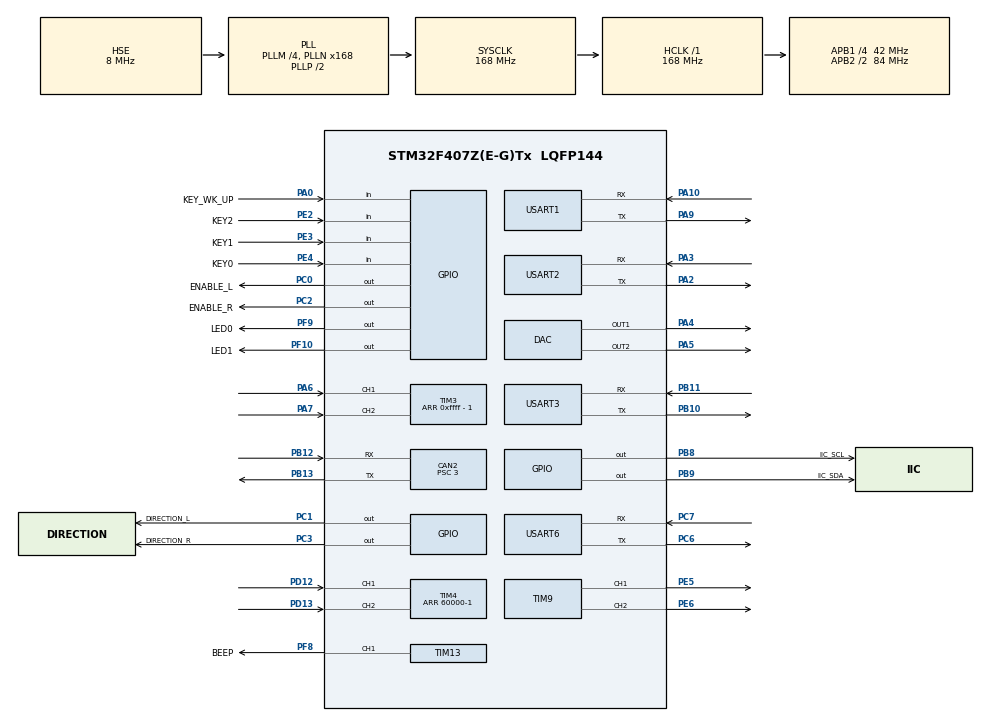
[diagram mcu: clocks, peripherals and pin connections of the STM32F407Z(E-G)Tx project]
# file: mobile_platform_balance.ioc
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CAN2.BS1=CAN_BS1_9TQ
CAN2.BS2=CAN_BS2_4TQ
CAN2.CalculateTimeQuantum=71.42857142857143
CAN2.Prescaler=3
CAN2.TXFP=ENABLE
Dma.Request0=USART2_RX
Dma.Request1=USART2_TX
Dma.Request2=USART6_RX
Dma.Request3=USART6_TX
Dma.Request4=USART1_RX
Dma.Request5=USART1_TX
Dma.Request6=USART3_RX
Dma.Request7=USART3_TX
Dma.USART1_RX.4.Direction=DMA_PERIPH_TO_MEMORY
Dma.USART1_RX.4.FIFOMode=DMA_FIFOMODE_DISABLE
Dma.USART1_RX.4.Instance=DMA2_Stream2
Dma.USART1_RX.4.MemDataAlignment=DMA_MDATAALIGN_BYTE
Dma.USART1_RX.4.MemInc=DMA_MINC_ENABLE
Dma.USART1_RX.4.Mode=DMA_NORMAL
Dma.USART1_RX.4.PeriphDataAlignment=DMA_PDATAALIGN_BYTE
Dma.USART1_RX.4.PeriphInc=DMA_PINC_DISABLE
Dma.USART1_RX.4.Priority=DMA_PRIORITY_LOW
Dma.USART1_TX.5.Direction=DMA_MEMORY_TO_PERIPH
Dma.USART1_TX.5.FIFOMode=DMA_FIFOMODE_DISABLE
Dma.USART1_TX.5.Instance=DMA2_Stream7
Dma.USART1_TX.5.MemDataAlignment=DMA_MDATAALIGN_BYTE
Dma.USART1_TX.5.MemInc=DMA_MINC_ENABLE
Dma.USART1_TX.5.Mode=DMA_NORMAL
Dma.USART1_TX.5.PeriphDataAlignment=DMA_PDATAALIGN_BYTE
Dma.USART1_TX.5.PeriphInc=DMA_PINC_DISABLE
Dma.USART1_TX.5.Priority=DMA_PRIORITY_LOW
Dma.USART2_RX.0.Direction=DMA_PERIPH_TO_MEMORY
Dma.USART2_RX.0.FIFOMode=DMA_FIFOMODE_DISABLE
Dma.USART2_RX.0.Instance=DMA1_Stream5
Dma.USART2_RX.0.MemDataAlignment=DMA_MDATAALIGN_BYTE
Dma.USART2_RX.0.MemInc=DMA_MINC_ENABLE
Dma.USART2_RX.0.Mode=DMA_NORMAL
Dma.USART2_RX.0.PeriphDataAlignment=DMA_PDATAALIGN_BYTE
Dma.USART2_RX.0.PeriphInc=DMA_PINC_DISABLE
Dma.USART2_RX.0.Priority=DMA_PRIORITY_LOW
Dma.USART2_TX.1.Direction=DMA_MEMORY_TO_PERIPH
Dma.USART2_TX.1.FIFOMode=DMA_FIFOMODE_DISABLE
Dma.USART2_TX.1.Instance=DMA1_Stream6
Dma.USART2_TX.1.MemDataAlignment=DMA_MDATAALIGN_BYTE
Dma.USART2_TX.1.MemInc=DMA_MINC_ENABLE
Dma.USART2_TX.1.Mode=DMA_NORMAL
Dma.USART2_TX.1.PeriphDataAlignment=DMA_PDATAALIGN_BYTE
Dma.USART2_TX.1.PeriphInc=DMA_PINC_DISABLE
Dma.USART2_TX.1.Priority=DMA_PRIORITY_LOW
Dma.USART3_RX.6.Direction=DMA_PERIPH_TO_MEMORY
Dma.USART3_RX.6.FIFOMode=DMA_FIFOMODE_DISABLE
Dma.USART3_RX.6.Instance=DMA1_Stream1
Dma.USART3_RX.6.MemDataAlignment=DMA_MDATAALIGN_BYTE
Dma.USART3_RX.6.MemInc=DMA_MINC_ENABLE
Dma.USART3_RX.6.Mode=DMA_NORMAL
Dma.USART3_RX.6.PeriphDataAlignment=DMA_PDATAALIGN_BYTE
Dma.USART3_RX.6.PeriphInc=DMA_PINC_DISABLE
Dma.USART3_RX.6.Priority=DMA_PRIORITY_LOW
Dma.USART3_TX.7.Direction=DMA_MEMORY_TO_PERIPH
Dma.USART3_TX.7.FIFOMode=DMA_FIFOMODE_DISABLE
Dma.USART3_TX.7.Instance=DMA1_Stream3
Dma.USART3_TX.7.MemDataAlignment=DMA_MDATAALIGN_BYTE
Dma.USART3_TX.7.MemInc=DMA_MINC_ENABLE
Dma.USART3_TX.7.Mode=DMA_NORMAL
Dma.USART3_TX.7.PeriphDataAlignment=DMA_PDATAALIGN_BYTE
Dma.USART3_TX.7.PeriphInc=DMA_PINC_DISABLE
Dma.USART3_TX.7.Priority=DMA_PRIORITY_LOW
Dma.USART6_RX.2.Direction=DMA_PERIPH_TO_MEMORY
Dma.USART6_RX.2.FIFOMode=DMA_FIFOMODE_DISABLE
Dma.USART6_RX.2.Instance=DMA2_Stream1
Dma.USART6_RX.2.MemDataAlignment=DMA_MDATAALIGN_BYTE
Dma.USART6_RX.2.MemInc=DMA_MINC_ENABLE
Dma.USART6_RX.2.Mode=DMA_NORMAL
Dma.USART6_RX.2.PeriphDataAlignment=DMA_PDATAALIGN_BYTE
Dma.USART6_RX.2.PeriphInc=DMA_PINC_DISABLE
Dma.USART6_RX.2.Priority=DMA_PRIORITY_LOW
Dma.USART6_TX.3.Direction=DMA_MEMORY_TO_PERIPH
Dma.USART6_TX.3.FIFOMode=DMA_FIFOMODE_DISABLE
Dma.USART6_TX.3.Instance=DMA2_Stream6
Dma.USART6_TX.3.MemDataAlignment=DMA_MDATAALIGN_BYTE
Dma.USART6_TX.3.MemInc=DMA_MINC_ENABLE
Dma.USART6_TX.3.Mode=DMA_NORMAL
Dma.USART6_TX.3.PeriphDataAlignment=DMA_PDATAALIGN_BYTE
Dma.USART6_TX.3.PeriphInc=DMA_PINC_DISABLE
Dma.USART6_TX.3.Priority=DMA_PRIORITY_LOW
FREERTOS.INCLUDE_vTaskDelayUntil=1
FREERTOS.Tasks01=defaultTask,0,128,StartDefaultTask,Default,NULL
Mcu.Family=STM32F4
Mcu.Name=STM32F407Z(E-G)Tx
Mcu.Package=LQFP144
NVIC.CAN2_RX1_IRQn=true\:5\:0\:false\:false\:true\:true\:true
NVIC.CAN2_TX_IRQn=true\:5\:0\:false\:false\:true\:true\:true
NVIC.DMA1_Stream1_IRQn=true\:5\:0\:false\:false\:true\:true\:false
NVIC.DMA1_Stream3_IRQn=true\:5\:0\:false\:false\:true\:true\:false
NVIC.DMA1_Stream5_IRQn=true\:5\:0\:false\:false\:true\:true\:false
NVIC.DMA1_Stream6_IRQn=true\:5\:0\:false\:false\:true\:true\:false
NVIC.DMA2_Stream1_IRQn=true\:5\:0\:false\:false\:true\:true\:false
NVIC.DMA2_Stream2_IRQn=true\:5\:0\:false\:false\:true\:true\:false
NVIC.DMA2_Stream6_IRQn=true\:5\:0\:false\:false\:true\:true\:false
NVIC.DMA2_Stream7_IRQn=true\:5\:0\:false\:false\:true\:true\:false
NVIC.PriorityGroup=NVIC_PRIORITYGROUP_4
NVIC.TIM1_BRK_TIM9_IRQn=true\:5\:0\:false\:false\:true\:true\:true
NVIC.TIM3_IRQn=true\:5\:0\:false\:false\:true\:true\:true
NVIC.TIM4_IRQn=true\:5\:0\:false\:false\:true\:true\:true
NVIC.USART1_IRQn=true\:5\:0\:false\:false\:true\:true\:true
NVIC.USART2_IRQn=true\:5\:0\:false\:false\:true\:true\:true
NVIC.USART3_IRQn=true\:5\:0\:false\:false\:true\:true\:true
NVIC.USART6_IRQn=true\:5\:0\:false\:false\:true\:true\:true
PA0-WKUP.GPIO_Label=KEY_WK_UP
PA0-WKUP.GPIO_PuPd=GPIO_PULLDOWN
PA0-WKUP.Signal=GPIO_Input
PA10.Mode=Asynchronous
PA10.Signal=USART1_RX
PA13.Mode=Serial_Wire
PA13.Signal=SYS_JTMS-SWDIO
PA14.Mode=Serial_Wire
PA14.Signal=SYS_JTCK-SWCLK
PA2.Mode=Asynchronous
PA2.Signal=USART2_TX
PA3.Mode=Asynchronous
PA3.Signal=USART2_RX
PA4.Signal=COMP_DAC1_group
PA5.Signal=COMP_DAC2_group
PA6.Signal=S_TIM3_CH1
PA7.Signal=S_TIM3_CH2
PA9.Mode=Asynchronous
PA9.Signal=USART1_TX
PB10.Mode=Asynchronous
PB10.Signal=USART3_TX
PB11.Mode=Asynchronous
PB11.Signal=USART3_RX
PB12.Mode=Slave
PB12.Signal=CAN2_RX
PB13.Mode=Slave
PB13.Signal=CAN2_TX
PB3.GPIO_PuPd=GPIO_PULLDOWN
PB3.Signal=S_TIM2_CH2
PB8.GPIO_Label=IIC_SCL
PB8.GPIO_PuPd=GPIO_PULLUP
PB8.Signal=GPIO_Output
PB9.GPIO_Label=IIC_SDA
PB9.GPIO_PuPd=GPIO_PULLUP
PB9.Signal=GPIO_Output
PC0.GPIO_Label=ENABLE_L
PC0.Signal=GPIO_Output
PC1.GPIO_Label=DIRECTION_L
PC1.Signal=GPIO_Output
PC2.GPIO_Label=ENABLE_R
PC2.Signal=GPIO_Output
PC3.GPIO_Label=DIRECTION_R
PC3.Signal=GPIO_Output
PC6.Mode=Asynchronous
PC6.Signal=USART6_TX
PC7.Mode=Asynchronous
PC7.Signal=USART6_RX
PD12.Signal=S_TIM4_CH1
PD13.Signal=S_TIM4_CH2
PE2.GPIO_Label=KEY2
PE2.GPIO_PuPd=GPIO_PULLUP
PE2.Signal=GPIO_Input
PE3.GPIO_Label=KEY1
PE3.GPIO_PuPd=GPIO_PULLUP
PE3.Signal=GPIO_Input
PE4.GPIO_Label=KEY0
PE4.GPIO_PuPd=GPIO_PULLUP
PE4.Signal=GPIO_Input
PE5.GPIO_PuPd=GPIO_PULLDOWN
PE5.Signal=S_TIM9_CH1
PE6.GPIO_PuPd=GPIO_PULLDOWN
PE6.Signal=S_TIM9_CH2
PF10.GPIO_Label=LED1
PF10.Signal=GPIO_Output
PF8.GPIO_Label=BEEP
PF8.Signal=S_TIM13_CH1
PF9.GPIO_Label=LED0
PF9.Signal=GPIO_Output
PH0-OSC_IN.Mode=HSE-External-Oscillator
PH0-OSC_IN.Signal=RCC_OSC_IN
PH1-OSC_OUT.Mode=HSE-External-Oscillator
PH1-OSC_OUT.Signal=RCC_OSC_OUT
ProjectManager.HeapSize=0x1000
ProjectManager.StackSize=0x2000
ProjectManager.TargetToolchain=MDK-ARM V5
RCC.48MHZClocksFreq_Value=84000000
RCC.AHBFreq_Value=168000000
RCC.APB1CLKDivider=RCC_HCLK_DIV4
RCC.APB1Freq_Value=42000000
RCC.APB1TimFreq_Value=84000000
RCC.APB2CLKDivider=RCC_HCLK_DIV2
RCC.APB2Freq_Value=84000000
RCC.APB2TimFreq_Value=168000000
RCC.CortexFreq_Value=168000000
RCC.HCLKFreq_Value=168000000
RCC.HSE_VALUE=8000000
RCC.HSI_VALUE=16000000
RCC.LSE_VALUE=32768
RCC.PLLM=4
RCC.PLLN=168
RCC.PLLSourceVirtual=RCC_PLLSOURCE_HSE
RCC.SYSCLKFreq_VALUE=168000000
RCC.SYSCLKSource=RCC_SYSCLKSOURCE_PLLCLK
RCC.VCOOutputFreq_Value=336000000
SH.COMP_DAC1_group.0=DAC_OUT1,DAC_OUT1
SH.COMP_DAC2_group.0=DAC_OUT2,DAC_OUT2
SH.S_TIM13_CH1.0=TIM13_CH1,PWM Generation1 CH1
SH.S_TIM2_CH2.0=TIM2_CH2
SH.S_TIM3_CH1.0=TIM3_CH1,Encoder_Interface
SH.S_TIM3_CH2.0=TIM3_CH2,Encoder_Interface
SH.S_TIM4_CH1.0=TIM4_CH1,Encoder_Interface
SH.S_TIM4_CH2.0=TIM4_CH2,Encoder_Interface
SH.S_TIM9_CH1.0=TIM9_CH1,PWM Generation1 CH1
SH.S_TIM9_CH2.0=TIM9_CH2,PWM Generation2 CH2
TIM13.Channel=TIM_CHANNEL_1
TIM3.EncoderMode=TIM_ENCODERMODE_TI12
TIM3.Period=0xffff - 1
TIM4.EncoderMode=TIM_ENCODERMODE_TI12
TIM4.Period=60000-1
TIM9.Channel-PWM\ Generation1\ CH1=TIM_CHANNEL_1
TIM9.Channel-PWM\ Generation2\ CH2=TIM_CHANNEL_2
USART1.VirtualMode=VM_ASYNC
USART2.VirtualMode=VM_ASYNC
USART3.VirtualMode=VM_ASYNC
USART6.VirtualMode=VM_ASYNC
VP_FREERTOS_VS_ENABLE.Mode=Enabled
VP_TIM13_VS_ClockSourceINT.Mode=Enable_Timer
board=custom

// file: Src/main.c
/**
  ******************************************************************************
  * @file           : main.c
  * @brief          : Main program body
  ******************************************************************************
  * This notice applies to any and all portions of this file
  * that are not between comment pairs USER CODE BEGIN and
  * USER CODE END. Other portions of this file, whether
  * inserted by the user or by software development tools
  * are owned by their respective copyright owners.
  *
  * Copyright (c) 2019 STMicroelectronics International N.V.
  * All rights reserved.
  *
  * Redistribution and use in source and binary forms, with or without
  * modification, are permitted, provided that the following conditions are met:
  *
  * 1. Redistribution of source code must retain the above copyright notice,
  *    this list of conditions and the following disclaimer.
  * 2. Redistributions in binary form must reproduce the above copyright notice,
  *    this list of conditions and the following disclaimer in the documentation
  *    and/or other materials provided with the distribution.
  * 3. Neither the name of STMicroelectronics nor the names of other
  *    contributors to this software may be used to endorse or promote products
  *    derived from this software without specific written permission.
  * 4. This software, including modifications and/or derivative works of this
  *    software, must execute solely and exclusively on microcontroller or
  *    microprocessor devices manufactured by or for STMicroelectronics.
  * 5. Redistribution and use of this software other than as permitted under
  *    this license is void and will automatically terminate your rights under
  *    this license.
  *
  * THIS SOFTWARE IS PROVIDED BY STMICROELECTRONICS AND CONTRIBUTORS "AS IS"
  * AND ANY EXPRESS, IMPLIED OR STATUTORY WARRANTIES, INCLUDING, BUT NOT
  * LIMITED TO, THE IMPLIED WARRANTIES OF MERCHANTABILITY, FITNESS FOR A
  * PARTICULAR PURPOSE AND NON-INFRINGEMENT OF THIRD PARTY INTELLECTUAL PROPERTY
  * RIGHTS ARE DISCLAIMED TO THE FULLEST EXTENT PERMITTED BY LAW. IN NO EVENT
  * SHALL STMICROELECTRONICS OR CONTRIBUTORS BE LIABLE FOR ANY DIRECT, INDIRECT,
  * INCIDENTAL, SPECIAL, EXEMPLARY, OR CONSEQUENTIAL DAMAGES (INCLUDING, BUT NOT
  * LIMITED TO, PROCUREMENT OF SUBSTITUTE GOODS OR SERVICES; LOSS OF USE, DATA,
  * OR PROFITS; OR BUSINESS INTERRUPTION) HOWEVER CAUSED AND ON ANY THEORY OF
  * LIABILITY, WHETHER IN CONTRACT, STRICT LIABILITY, OR TORT (INCLUDING
  * NEGLIGENCE OR OTHERWISE) ARISING IN ANY WAY OUT OF THE USE OF THIS SOFTWARE,
  * EVEN IF ADVISED OF THE POSSIBILITY OF SUCH DAMAGE.
  *
  ******************************************************************************
  */
#include "main.h"
#include "stm32f4xx_hal.h"
#include "cmsis_os.h"
#include "can.h"
#include "dac.h"
#include "dma.h"
#include "tim.h"
#include "usart.h"
#include "gpio.h"

/* USER CODE BEGIN Includes */
#include "sys_config.h"
/* USER CODE END Includes */

/* USER CODE BEGIN PV */
/* Private variables ---------------------------------------------------------*/

/* USER CODE END PV */

void SystemClock_Config(void);
void MX_FREERTOS_Init(void);

/* USER CODE BEGIN PFP */
/* Private function prototypes -----------------------------------------------*/

/* USER CODE END PFP */

int main(void)
{

  /* MCU Configuration----------------------------------------------------------*/

  /* Reset of all peripherals, Initializes the Flash interface and the Systick. */
  HAL_Init();

  /* Configure the system clock */
  SystemClock_Config();

  /* Initialize all configured peripherals */
  MX_GPIO_Init();
  MX_DMA_Init();
  MX_USART1_UART_Init();
  MX_TIM13_Init();
  MX_CAN2_Init();
  MX_USART2_UART_Init();
  MX_USART3_UART_Init();
  MX_USART6_UART_Init();
  MX_TIM3_Init();
  MX_TIM4_Init();
  MX_TIM9_Init();
  MX_DAC_Init();
  /* USER CODE BEGIN 2 */
	can_filter_init(&hcan2);
  /* USER CODE END 2 */

  /* Call init function for freertos objects (in freertos.c) */
  MX_FREERTOS_Init();

  /* Start scheduler */
  osKernelStart();

  /* We should never get here as control is now taken by the scheduler */

  /* Infinite loop */
  while (1)
  {

  }

}

void SystemClock_Config(void)
{

  RCC_OscInitTypeDef RCC_OscInitStruct;
  RCC_ClkInitTypeDef RCC_ClkInitStruct;

    /**Configure the main internal regulator output voltage
    */
  __HAL_RCC_PWR_CLK_ENABLE();

  __HAL_PWR_VOLTAGESCALING_CONFIG(PWR_REGULATOR_VOLTAGE_SCALE1);

    /**Initializes the CPU, AHB and APB busses clocks
    */
  RCC_OscInitStruct.OscillatorType = RCC_OSCILLATORTYPE_HSE;
  RCC_OscInitStruct.HSEState = RCC_HSE_ON;
  RCC_OscInitStruct.PLL.PLLState = RCC_PLL_ON;
  RCC_OscInitStruct.PLL.PLLSource = RCC_PLLSOURCE_HSE;
  RCC_OscInitStruct.PLL.PLLM = 4;
  RCC_OscInitStruct.PLL.PLLN = 168;
  RCC_OscInitStruct.PLL.PLLP = RCC_PLLP_DIV2;
  RCC_OscInitStruct.PLL.PLLQ = 4;
  if (HAL_RCC_OscConfig(&RCC_OscInitStruct) != HAL_OK)
  {
    _Error_Handler(__FILE__, __LINE__);
  }

    /**Initializes the CPU, AHB and APB busses clocks
    */
  RCC_ClkInitStruct.ClockType = RCC_CLOCKTYPE_HCLK|RCC_CLOCKTYPE_SYSCLK
                              |RCC_CLOCKTYPE_PCLK1|RCC_CLOCKTYPE_PCLK2;
  RCC_ClkInitStruct.SYSCLKSource = RCC_SYSCLKSOURCE_PLLCLK;
  RCC_ClkInitStruct.AHBCLKDivider = RCC_SYSCLK_DIV1;
  RCC_ClkInitStruct.APB1CLKDivider = RCC_HCLK_DIV4;
  RCC_ClkInitStruct.APB2CLKDivider = RCC_HCLK_DIV2;

  if (HAL_RCC_ClockConfig(&RCC_ClkInitStruct, FLASH_LATENCY_5) != HAL_OK)
  {
    _Error_Handler(__FILE__, __LINE__);
  }

    /**Configure the Systick interrupt time
    */
  HAL_SYSTICK_Config(HAL_RCC_GetHCLKFreq()/1000);

    /**Configure the Systick
    */
  HAL_SYSTICK_CLKSourceConfig(SYSTICK_CLKSOURCE_HCLK);

  /* SysTick_IRQn interrupt configuration */
  HAL_NVIC_SetPriority(SysTick_IRQn, 15, 0);
}

void _Error_Handler(char *file, int line)
{
  while(1)
  {
  }
}

/************************ (C) COPYRIGHT STMicroelectronics *****END OF FILE****/

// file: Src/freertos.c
/* USER CODE BEGIN Header */
/**
  ******************************************************************************
  * File Name          : freertos.c
  * Description        : Code for freertos applications
  ******************************************************************************
  * This notice applies to any and all portions of this file
  * that are not between comment pairs USER CODE BEGIN and
  * USER CODE END. Other portions of this file, whether
  * inserted by the user or by software development tools
  * are owned by their respective copyright owners.
  *
  * Copyright (c) 2018 STMicroelectronics International N.V.
  * All rights reserved.
  *
  * Redistribution and use in source and binary forms, with or without
  * modification, are permitted, provided that the following conditions are met:
  *
  * 1. Redistribution of source code must retain the above copyright notice,
  *    this list of conditions and the following disclaimer.
  * 2. Redistributions in binary form must reproduce the above copyright notice,
  *    this list of conditions and the following disclaimer in the documentation
  *    and/or other materials provided with the distribution.
  * 3. Neither the name of STMicroelectronics nor the names of other
  *    contributors to this software may be used to endorse or promote products
  *    derived from this software without specific written permission.
  * 4. This software, including modifications and/or derivative works of this
  *    software, must execute solely and exclusively on microcontroller or
  *    microprocessor devices manufactured by or for STMicroelectronics.
  * 5. Redistribution and use of this software other than as permitted under
  *    this license is void and will automatically terminate your rights under
  *    this license.
  *
  * THIS SOFTWARE IS PROVIDED BY STMICROELECTRONICS AND CONTRIBUTORS "AS IS"
  * AND ANY EXPRESS, IMPLIED OR STATUTORY WARRANTIES, INCLUDING, BUT NOT
  * LIMITED TO, THE IMPLIED WARRANTIES OF MERCHANTABILITY, FITNESS FOR A
  * PARTICULAR PURPOSE AND NON-INFRINGEMENT OF THIRD PARTY INTELLECTUAL PROPERTY
  * RIGHTS ARE DISCLAIMED TO THE FULLEST EXTENT PERMITTED BY LAW. IN NO EVENT
  * SHALL STMICROELECTRONICS OR CONTRIBUTORS BE LIABLE FOR ANY DIRECT, INDIRECT,
  * INCIDENTAL, SPECIAL, EXEMPLARY, OR CONSEQUENTIAL DAMAGES (INCLUDING, BUT NOT
  * LIMITED TO, PROCUREMENT OF SUBSTITUTE GOODS OR SERVICES; LOSS OF USE, DATA,
  * OR PROFITS; OR BUSINESS INTERRUPTION) HOWEVER CAUSED AND ON ANY THEORY OF
  * LIABILITY, WHETHER IN CONTRACT, STRICT LIABILITY, OR TORT (INCLUDING
  * NEGLIGENCE OR OTHERWISE) ARISING IN ANY WAY OUT OF THE USE OF THIS SOFTWARE,
  * EVEN IF ADVISED OF THE POSSIBILITY OF SUCH DAMAGE.
  *
  ******************************************************************************
  */
/* USER CODE END Header */

#include "FreeRTOS.h"
#include "task.h"
#include "main.h"
#include "cmsis_os.h"

/* USER CODE BEGIN Includes */
#include "sys_config.h"
//#include "ctrl_task.h"
/* USER CODE END Includes */

/* USER CODE BEGIN Variables */
osThreadId ctrl_TaskHandle;
osThreadId get_imu_TaskHandle;
osThreadId key_scan_TaskHandle;
osThreadId led_scan_TaskHandle;

/* USER CODE END Variables */
osThreadId defaultTaskHandle;

void StartDefaultTask(void const * argument);

void MX_FREERTOS_Init(void); /* (MISRA C 2004 rule 8.1) */

void MX_FREERTOS_Init(void) {

  /* Create the thread(s) */
  /* definition and creation of defaultTask */
  osThreadDef(defaultTask, StartDefaultTask, osPriorityNormal, 0, 128);
  defaultTaskHandle = osThreadCreate(osThread(defaultTask), NULL);

  /* USER CODE BEGIN RTOS_THREADS */
  /* add threads, ... */
	osThreadDef(lcd_scan_task, start_lcd_scan_task, osPriorityNormal, 0, 500);
	led_scan_TaskHandle = osThreadCreate(osThread(lcd_scan_task), NULL);
//
	osThreadDef(get_imu_task, start_get_imu_task, osPriorityAboveNormal, 0, 500);
	get_imu_TaskHandle = osThreadCreate(osThread(get_imu_task), NULL);

//	osThreadDef(ctrl_task, start_ctrl_task, osPriorityNormal, 0, 128);
//	ctrl_TaskHandle = osThreadCreate(osThread(ctrl_task), NULL);

//	osThreadDef(key_scan_task, start_key_scan_task, osPriorityNormal, 0, 500);
//	key_scan_TaskHandle = osThreadCreate(osThread(key_scan_task), NULL);

  /* USER CODE END RTOS_THREADS */

}

void StartDefaultTask(void const * argument)
{

  /* USER CODE BEGIN StartDefaultTask */
  /* Infinite loop */
  for(;;)
  {
		led_blink(LED1, 1, 1000);
    osDelay(1);
  }
  /* USER CODE END StartDefaultTask */
}

/************************ (C) COPYRIGHT STMicroelectronics *****END OF FILE****/
